# ATtiny88 register map
Vendor: Atmel; File version: 1.0
CPU: other r0p0, little endian, no MPU, no FPU, 4 interrupt priority bits
Registers are 8-bit, read-write, reset 0x0 unless marked. A register's access mark holds for its fields unless they carry their own. Offsets are from the block's base; [hi:lo] are bit positions; {n}, {i} and the like mark numbered series; 'fields as' and 'values as' point back to an identical list.

## CPU — CPU Registers
Base 0x00800032
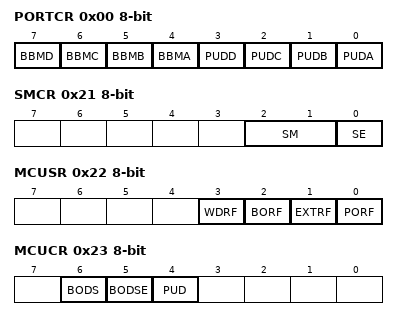
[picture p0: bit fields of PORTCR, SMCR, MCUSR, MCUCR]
0x00 PORTCR — Port Configuration Register (read-only for debugger)
  [7] BBMD, [6] BBMC, [5] BBMB, [4] BBMA, [3] PUDD, [2] PUDC, [1] PUDB, [0] PUDA
0x0C GPIOR0 — General Purpose I/O Register 0
0x18 GPIOR1 — General Purpose I/O Register 1
0x19 GPIOR2 — General Purpose I/O Register 2
0x21 SMCR — Sleep Mode Control Register
  [2:1] SM — Sleep Mode
    0=IDLE; 1=ADC (ADC Noise Reduction (If Available)); 2=PDOWN (Power Down); 3=PSAVE (Power Save)
  [0] SE — Sleep Enable
0x22 MCUSR — MCU Status Register
  [3] WDRF — Watchdog Reset Flag
  [2] BORF — Brown-out Reset Flag
  [1] EXTRF — External Reset Flag
  [0] PORF — Power-on reset flag
0x23 MCUCR — MCU Control Register
  [6] BODS — BOD Sleep
  [5] BODSE — BOD Sleep Enable
  [4] PUD — Pull-up Disable
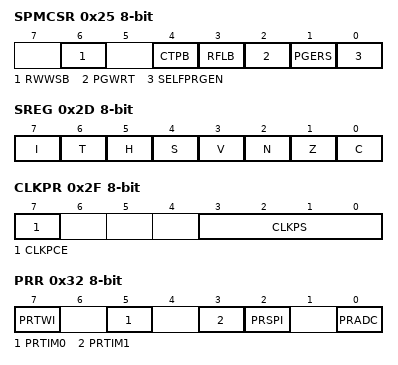
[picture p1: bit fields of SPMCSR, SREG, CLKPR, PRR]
0x25 SPMCSR — Store Program Memory Control Register
  [6] RWWSB — Read-While-Write Section Busy
  [4] CTPB — Clear Temporary Page Buffer
  [3] RFLB — Read Fuse and Lock Bits
  [2] PGWRT — Page Write
  [1] PGERS — Page Erase
  [0] SELFPRGEN — Self Programming Enable
0x2B SPL — Stack Pointer Low
0x2C SPH — Stack Pointer High
0x2D SREG — Status Register
  [7] I — Global Interrupt Enable
  [6] T — Bit Copy Storage
  [5] H — Half Carry Flag
  [4] S — Sign Bit
  [3] V — Two's Complement Overflow Flag
  [2] N — Negative Flag
  [1] Z — Zero Flag
  [0] C — Carry Flag
0x2F CLKPR — Clock Prescale Register (read-only for debugger)
  [7] CLKPCE — Clock Prescaler Change Enable
  [3:0] CLKPS — Clock Prescaler Select Bits
    0=1; 1=2; 2=4; 3=8; 4=16; 5=32; 6=64; 7=128; 8=256
0x32 PRR — Power Reduction Register (read-only for debugger)
  [7] PRTWI — Power Reduction TWI
  [5] PRTIM0 — Power Reduction Timer/Counter0
  [3] PRTIM1 — Power Reduction Timer/Counter1
  [2] PRSPI — Power Reduction Serial Peripheral Interface
  [0] PRADC — Power Reduction ADC
0x34 OSCCAL — Oscillator Calibration Value (read-only for debugger)
  [7:0] OSCCAL — Oscillator Calibration

## EEPROM
Base 0x0080003F
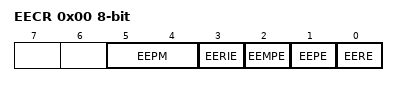
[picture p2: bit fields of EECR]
0x00 EECR — EEPROM Control Register
  [5:4] EEPM — EEPROM Programming Mode Bits
    0=ERASE_AND_WRITE_IN_ONE_OPERATION; 1=ERASE_ONLY; 2=WRITE_ONLY
  [3] EERIE — EEPROM Ready Interrupt Enable
  [2] EEMPE — EEPROM Master Write Enable
  [1] EEPE — EEPROM Write Enable
  [0] EERE — EEPROM Read Enable
0x01 EEDR — EEPROM Data Register
0x02 EEARL — EEPROM Address Register Low Byte

## EXINT — External Interrupts
Base 0x0080003B
0x00 PCIFR — Pin Change Interrupt Flag Register (read-only for debugger)
  [3:0] PCIF — Pin Change Interrupt Flags
0x01 EIFR — External Interrupt Flag Register (read-only for debugger)
  [1:0] INTF — External Interrupt Flags
0x02 EIMSK — External Interrupt Mask Register
  [1:0] INT — External Interrupt Request 1 Enable
0x2D PCICR
  [3:0] PCIE
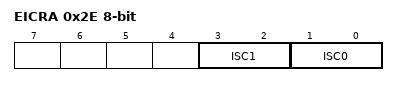
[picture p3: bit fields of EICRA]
0x2E EICRA — External Interrupt Control Register
  [3:2] ISC1 — External Interrupt Sense Control 1 Bits
    0=LOW_LEVEL_OF_INTX; 1=ANY_LOGICAL_CHANGE_IN_INTX; 2=FALLING_EDGE_OF_INTX; 3=RISING_EDGE_OF_INTX
  [1:0] ISC0 — External Interrupt Sense Control 0 Bits
    values as ISC1
0x2F PCMSK3 — Pin Change Mask Register 3
  [3:0] PCINT — Pin Change Enable Masks
{0x30+i} PCMSK{i} (i=0..2) — Pin Change Mask Register {i}
  [7:0] PCINT — Pin Change Enable Masks

## PORTA — I/O Port
Base 0x0080002C
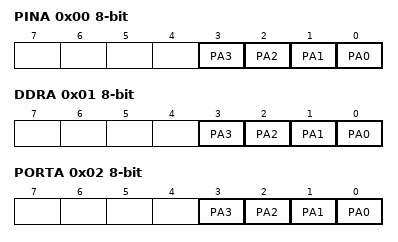
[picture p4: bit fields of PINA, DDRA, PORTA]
0x00 PINA — Port A Input Pins (read-only for debugger)
  [n] PA{n} (n=0..3) — Pin A{n}
0x01 DDRA — Port A Data Direction Register (read-only for debugger)
  [n] PA{n} (n=0..3) — Pin A{n}
0x02 PORTA — Port A Data Register (read-only for debugger)
  [n] PA{n} (n=0..3) — Pin A{n}

## PORTB — I/O Port
Base 0x00800023
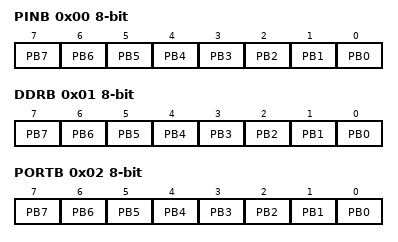
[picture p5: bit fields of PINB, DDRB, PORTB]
0x00 PINB — Port B Input Pins (read-only for debugger)
  [n] PB{n} (n=0..7) — Pin B{n}
0x01 DDRB — Port B Data Direction Register
  [n] PB{n} (n=0..7) — Pin B{n}
0x02 PORTB — Port B Data Register
  [n] PB{n} (n=0..7) — Pin B{n}
